# apollo4p register map
Vendor: Ambiq Micro; Series: Apollo; File version: 1.0
CPU: CM4 r1p0, little endian, MPU, FPU, I-cache, D-cache, VTOR, ITCM, DTCM, 3 interrupt priority bits, 0 interrupts
Registers are 32-bit, read-write, reset 0x0 unless marked. A register's access mark holds for its fields unless they carry their own. Offsets are from the block's base; [hi:lo] are bit positions; {n}, {i} and the like mark numbered series; 'fields as' and 'values as' point back to an identical list.

## GPIO (part 3 of 5) — General Purpose IO
Base 0x40010000
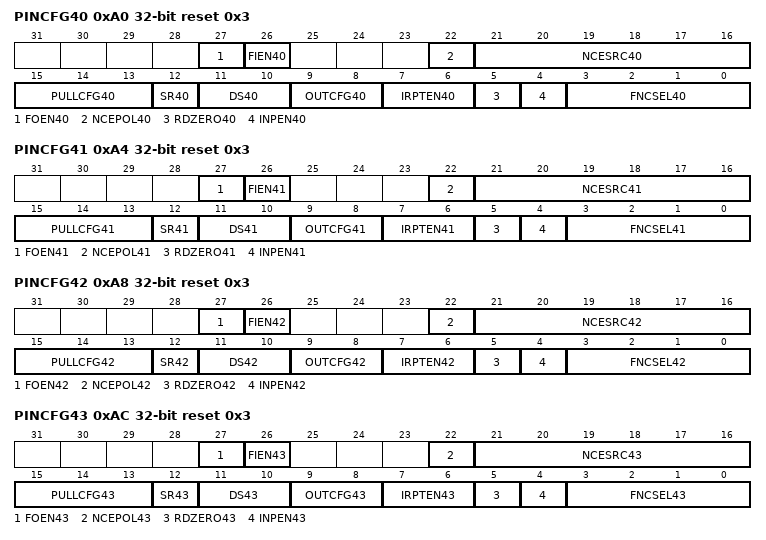
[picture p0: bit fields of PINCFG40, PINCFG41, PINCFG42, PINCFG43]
0xA0 PINCFG40 reset 0x3 — Controls the operation of GPIO pin 40.
  [27] FOEN40 — Force output enable active regardless of function selected. Otherwise the selected function will enable the output only when needed
  [26] FIEN40 — Force input enable active regardless of function selected. Otherwise the selected function will enable the input only when needed
  [22] NCEPOL40 — Polarity select for NCE for GPIO 40
    0=LOW (Polarity is active low); 1=HIGH (Polarity is active high)
  [21:16] NCESRC40 — IOMSTR/MSPI N Chip Select 40, DISP control signals DE, CSX, and CS. Polarity is determined by CE_POLARITY field
    {v}=IOM0CE{v} (IOM 0 NCE {v} module) (v=0..3); {v}=IOM1CE{v-4} (IOM 1 NCE {v-4} module) (v=4..7); {v}=IOM2CE{v-8} (IOM 2 NCE {v-8} module) (v=8..11); {v}=IOM3CE{v-12} (IOM 3 NCE {v-12} module) (v=12..15); {v}=IOM4CE{v-16} (IOM 4 NCE {v-16} module) (v=16..19); {v}=IOM5CE{v-20} (IOM 5 NCE {v-20} module) (v=20..23); {v}=IOM6CE{v-24} (IOM 6 NCE {v-24} module) (v=24..27); {v}=IOM7CE{v-28} (IOM 7 NCE {v-28} module) (v=28..31); 32=MSPI0CEN0 (MSPI 0 NCE 0 module); 33=MSPI0CEN1 (MSPI 0 NCE 1 module); 34=MSPI1CEN0 (MSPI 1 NCE 0 module); 35=MSPI1CEN1 (MSPI 1 NCE 1 module); 36=MSPI2CEN0 (MSPI 2 NCE 0 module); 37=MSPI2CEN1 (MSPI 2 NCE 1 module); 38=DC_DPI_DE (DC DPI DE module); 39=DISP_CONT_CSX (DISP CONT CSX module); 40=DC_SPI_CS_N (DC SPI CS_N module); 41=DC_QSPI_CS_N (DC QSPI CS_N module); 42=DC_RESX (DC module RESX)
  [15:13] PULLCFG40 — Pullup/Pulldown configuration for GPIO 40
    0=DIS (No pullup or pulldown selected); 1=PD50K (50K Pulldown selected); 2=PU15K (1.5K Pullup selected); 3=PU6K (6K Pullup selected); 4=PU12K (12K Pullup selected); 5=PU24K (24K Pullup selected); 6=PU50K (50K Pullup selected); 7=PU100K (100K Pullup selected)
  [12] SR40 — Configure the slew rate
  [11:10] DS40 — Drive strength selection for GPIO 40
    0=0P1X (0.1x output driver selected); 1=0P5X (0.5x output driver selected); 2=0P75X (0.75x output driver selected); 3=1P0X (1.0x output driver selected)
  [9:8] OUTCFG40 — Pin IO mode selection for GPIO pin 40
    0=DIS (Output Disabled); 1=PUSHPULL (Output configured in push pull mode. Will drive 0 and 1 values on pin.); 2=OD (Output configured in open drain mode. Will only drive pin low, tristate otherwise.); 3=TS (Output configured in Tristate-able push pull mode. Will drive 0, 1 of HiZ on pin.)
  [7:6] IRPTEN40 — Interrupt enable for GPIO 40
    0=DIS (Interrupts are disabled for this GPIO); 1=INTFALL (Interrupts are enabled for falling edge transition on this GPIO); 2=INTRISE (Interrupts are enabled for rising edge transitions on this GPIO); 3=INTANY (Interrupts are enabled for any edge transition on this GPIO)
  [5] RDZERO40 — Return 0 for read data on GPIO 40
  [4] INPEN40 — Input enable for GPIO 40
  [3:0] FNCSEL40 — Function select for GPIO pin 40
    0=MSPI1_3 (MSPI Master 1 Interface Signal); 1=TRIG1 (ADC trigger input); 2=SWTRACE1 (Serial Wire Debug Trace Output 1); 3=GPIO (General purpose I/O); 4=UART0CTS (UART Clear to Send (CTS) (UART 0)); 5=DISP_D18 (Display Data 18); 6=CT40 (Timer/Counter input or output; Selection of direction is done via CTIMER register settings.); 7=NCE40 (IOMSTR/MSPI N Chip Select. Polarity is determined by CE_POLARITY field); 8=OBSBUS8 (Observation bus bit 8); 11=FPIO (Fast PIO)
0xA4 PINCFG41 reset 0x3 — Controls the operation of GPIO pin 41.
  [27] FOEN41 — Force output enable active regardless of function selected. Otherwise the selected function will enable the output only when needed
  [26] FIEN41 — Force input enable active regardless of function selected. Otherwise the selected function will enable the input only when needed
  [22] NCEPOL41 — Polarity select for NCE for GPIO 41
    values as PINCFG40.NCEPOL40
  [21:16] NCESRC41 — IOMSTR/MSPI N Chip Select 41, DISP control signals DE, CSX, and CS. Polarity is determined by CE_POLARITY field
    values as PINCFG40.NCESRC40
  [15:13] PULLCFG41 — Pullup/Pulldown configuration for GPIO 41
    values as PINCFG40.PULLCFG40
  [12] SR41 — Configure the slew rate
  [11:10] DS41 — Drive strength selection for GPIO 41
    values as PINCFG40.DS40
  [9:8] OUTCFG41 — Pin IO mode selection for GPIO pin 41
    values as PINCFG40.OUTCFG40
  [7:6] IRPTEN41 — Interrupt enable for GPIO 41
    values as PINCFG40.IRPTEN40
  [5] RDZERO41 — Return 0 for read data on GPIO 41
  [4] INPEN41 — Input enable for GPIO 41
  [3:0] FNCSEL41 — Function select for GPIO pin 41
    0=MSPI1_4 (MSPI Master 1 Interface Signal); 1=TRIG0 (ADC trigger input); 2=SWTRACE2 (Serial Wire Debug Trace Output 2); 3=GPIO (General purpose I/O); 4=UART0TX (UART transmit output (UART 0)); 5=DISP_D19 (Display Data 19); 6=CT41 (Timer/Counter input or output; Selection of direction is done via CTIMER register settings.); 7=NCE41 (IOMSTR/MSPI N Chip Select. Polarity is determined by CE_POLARITY field); 8=OBSBUS9 (Observation bus bit 9); 9=SWO (Serial Wire Output); 11=FPIO (Fast PIO)
0xA8 PINCFG42 reset 0x3 — Controls the operation of GPIO pin 42.
  [27] FOEN42 — Force output enable active regardless of function selected. Otherwise the selected function will enable the output only when needed
  [26] FIEN42 — Force input enable active regardless of function selected. Otherwise the selected function will enable the input only when needed
  [22] NCEPOL42 — Polarity select for NCE for GPIO 42
    values as PINCFG40.NCEPOL40
  [21:16] NCESRC42 — IOMSTR/MSPI N Chip Select 42, DISP control signals DE, CSX, and CS. Polarity is determined by CE_POLARITY field
    values as PINCFG40.NCESRC40
  [15:13] PULLCFG42 — Pullup/Pulldown configuration for GPIO 42
    values as PINCFG40.PULLCFG40
  [12] SR42 — Configure the slew rate
  [11:10] DS42 — Drive strength selection for GPIO 42
    values as PINCFG40.DS40
  [9:8] OUTCFG42 — Pin IO mode selection for GPIO pin 42
    values as PINCFG40.OUTCFG40
  [7:6] IRPTEN42 — Interrupt enable for GPIO 42
    values as PINCFG40.IRPTEN40
  [5] RDZERO42 — Return 0 for read data on GPIO 42
  [4] INPEN42 — Input enable for GPIO 42
  [3:0] FNCSEL42 — Function select for GPIO pin 42
    0=MSPI1_5 (MSPI Master 1 Interface Signal); 1=TRIG2 (ADC trigger input); 2=SWTRACE3 (Serial Wire Debug Trace Output 3); 3=GPIO (General purpose I/O); 4=UART2TX (UART transmit output (UART 2)); 5=DISP_D20 (Display Data 20); 6=CT42 (Timer/Counter input or output; Selection of direction is done via CTIMER register settings.); 7=NCE42 (IOMSTR/MSPI N Chip Select. Polarity is determined by CE_POLARITY field); 8=OBSBUS10 (Observation bus bit 10); 11=FPIO (Fast PIO)
0xAC PINCFG43 reset 0x3 — Controls the operation of GPIO pin 43.
  [27] FOEN43 — Force output enable active regardless of function selected. Otherwise the selected function will enable the output only when needed
  [26] FIEN43 — Force input enable active regardless of function selected. Otherwise the selected function will enable the input only when needed
  [22] NCEPOL43 — Polarity select for NCE for GPIO 43
    values as PINCFG40.NCEPOL40
  [21:16] NCESRC43 — IOMSTR/MSPI N Chip Select 43, DISP control signals DE, CSX, and CS. Polarity is determined by CE_POLARITY field
    values as PINCFG40.NCESRC40
  [15:13] PULLCFG43 — Pullup/Pulldown configuration for GPIO 43
    values as PINCFG40.PULLCFG40
  [12] SR43 — Configure the slew rate
  [11:10] DS43 — Drive strength selection for GPIO 43
    values as PINCFG40.DS40
  [9:8] OUTCFG43 — Pin IO mode selection for GPIO pin 43
    values as PINCFG40.OUTCFG40
  [7:6] IRPTEN43 — Interrupt enable for GPIO 43
    values as PINCFG40.IRPTEN40
  [5] RDZERO43 — Return 0 for read data on GPIO 43
  [4] INPEN43 — Input enable for GPIO 43
  [3:0] FNCSEL43 — Function select for GPIO pin 43
    0=MSPI1_6 (MSPI Master 1 Interface Signal); 1=TRIG3 (ADC trigger input); 2=SWTRACECTL (Serial Wire Debug Trace Control); 3=GPIO (General purpose I/O); 4=UART0RX (UART receive input (UART 0)); 5=DISP_D21 (Display Data 21); 6=CT43 (Timer/Counter input or output; Selection of direction is done via CTIMER register settings.); 7=NCE43 (IOMSTR/MSPI N Chip Select. Polarity is determined by CE_POLARITY field); 8=OBSBUS11 (Observation bus bit 11); 11=FPIO (Fast PIO)
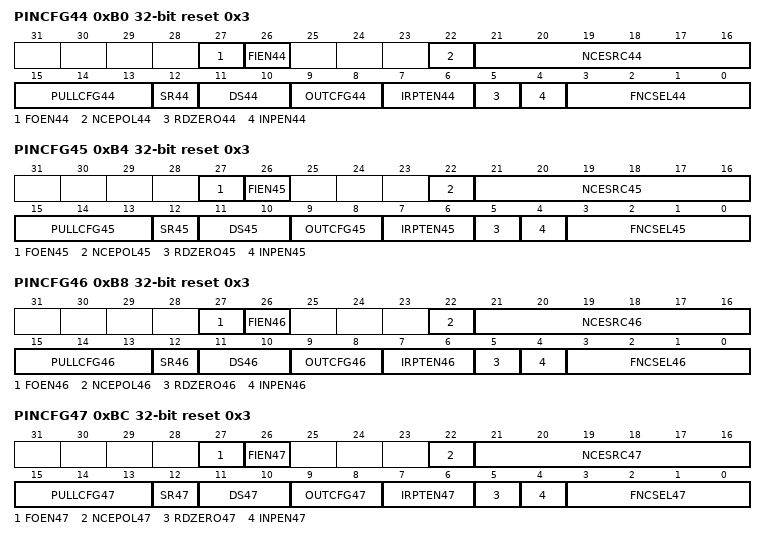
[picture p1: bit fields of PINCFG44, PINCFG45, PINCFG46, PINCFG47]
0xB0 PINCFG44 reset 0x3 — Controls the operation of GPIO pin 44.
  [27] FOEN44 — Force output enable active regardless of function selected. Otherwise the selected function will enable the output only when needed
  [26] FIEN44 — Force input enable active regardless of function selected. Otherwise the selected function will enable the input only when needed
  [22] NCEPOL44 — Polarity select for NCE for GPIO 44
    values as PINCFG40.NCEPOL40
  [21:16] NCESRC44 — IOMSTR/MSPI N Chip Select 44, DISP control signals DE, CSX, and CS. Polarity is determined by CE_POLARITY field
    values as PINCFG40.NCESRC40
  [15:13] PULLCFG44 — Pullup/Pulldown configuration for GPIO 44
    values as PINCFG40.PULLCFG40
  [12] SR44 — Configure the slew rate
  [11:10] DS44 — Drive strength selection for GPIO 44
    values as PINCFG40.DS40
  [9:8] OUTCFG44 — Pin IO mode selection for GPIO pin 44
    values as PINCFG40.OUTCFG40
  [7:6] IRPTEN44 — Interrupt enable for GPIO 44
    values as PINCFG40.IRPTEN40
  [5] RDZERO44 — Return 0 for read data on GPIO 44
  [4] INPEN44 — Input enable for GPIO 44
  [3:0] FNCSEL44 — Function select for GPIO pin 44
    0=MSPI1_7 (MSPI Master 1 Interface Signal); 1=TRIG1 (ADC trigger input); 2=SWO (Serial Wire Output); 3=GPIO (General purpose I/O); 4=UART2RX (UART receive input (UART 2)); 5=DISP_D22 (Display Data 22); 6=CT44 (Timer/Counter input or output; Selection of direction is done via CTIMER register settings.); 7=NCE44 (IOMSTR/MSPI N Chip Select. Polarity is determined by CE_POLARITY field); 8=OBSBUS12 (Observation bus bit 12); 9=VCMPO (Output of the voltage comparator signal); 11=FPIO (Fast PIO)
0xB4 PINCFG45 reset 0x3 — Controls the operation of GPIO pin 45.
  [27] FOEN45 — Force output enable active regardless of function selected. Otherwise the selected function will enable the output only when needed
  [26] FIEN45 — Force input enable active regardless of function selected. Otherwise the selected function will enable the input only when needed
  [22] NCEPOL45 — Polarity select for NCE for GPIO 45
    values as PINCFG40.NCEPOL40
  [21:16] NCESRC45 — IOMSTR/MSPI N Chip Select 45, DISP control signals DE, CSX, and CS. Polarity is determined by CE_POLARITY field
    values as PINCFG40.NCESRC40
  [15:13] PULLCFG45 — Pullup/Pulldown configuration for GPIO 45
    values as PINCFG40.PULLCFG40
  [12] SR45 — Configure the slew rate
  [11:10] DS45 — Drive strength selection for GPIO 45
    values as PINCFG40.DS40
  [9:8] OUTCFG45 — Pin IO mode selection for GPIO pin 45
    values as PINCFG40.OUTCFG40
  [7:6] IRPTEN45 — Interrupt enable for GPIO 45
    values as PINCFG40.IRPTEN40
  [5] RDZERO45 — Return 0 for read data on GPIO 45
  [4] INPEN45 — Input enable for GPIO 45
  [3:0] FNCSEL45 — Function select for GPIO pin 45
    0=MSPI1_8 (MSPI Master 1 Interface Signal); 1=TRIG2 (ADC trigger input); 2=32KHzXT (32kHZ from analog); 3=GPIO (General purpose I/O); 4=UART0TX (UART transmit output (UART 0)); 5=DISP_D23 (Display Data 23); 6=CT45 (Timer/Counter input or output; Selection of direction is done via CTIMER register settings.); 7=NCE45 (IOMSTR/MSPI N Chip Select. Polarity is determined by CE_POLARITY field); 8=OBSBUS13 (Observation bus bit 13); 11=FPIO (Fast PIO)
0xB8 PINCFG46 reset 0x3 — Controls the operation of GPIO pin 46.
  [27] FOEN46 — Force output enable active regardless of function selected. Otherwise the selected function will enable the output only when needed
  [26] FIEN46 — Force input enable active regardless of function selected. Otherwise the selected function will enable the input only when needed
  [22] NCEPOL46 — Polarity select for NCE for GPIO 46
    values as PINCFG40.NCEPOL40
  [21:16] NCESRC46 — IOMSTR/MSPI N Chip Select 46, DISP control signals DE, CSX, and CS. Polarity is determined by CE_POLARITY field
    values as PINCFG40.NCESRC40
  [15:13] PULLCFG46 — Pullup/Pulldown configuration for GPIO 46
    values as PINCFG40.PULLCFG40
  [12] SR46 — Configure the slew rate
  [11:10] DS46 — Drive strength selection for GPIO 46
    values as PINCFG40.DS40
  [9:8] OUTCFG46 — Pin IO mode selection for GPIO pin 46
    values as PINCFG40.OUTCFG40
  [7:6] IRPTEN46 — Interrupt enable for GPIO 46
    values as PINCFG40.IRPTEN40
  [5] RDZERO46 — Return 0 for read data on GPIO 46
  [4] INPEN46 — Input enable for GPIO 46
  [3:0] FNCSEL46 — Function select for GPIO pin 46
    0=MSPI1_9 (MSPI Master 1 Interface Signal); 1=TRIG3 (ADC trigger input); 2=CLKOUT_32M (32MHz Oscillator output clock); 3=GPIO (General purpose I/O); 4=UART2TX (UART transmit output (UART 2)); 5=UART3TX (UART transmit output (UART 3)); 6=CT46 (Timer/Counter input or output; Selection of direction is done via CTIMER register settings.); 7=NCE46 (IOMSTR/MSPI N Chip Select. Polarity is determined by CE_POLARITY field); 8=OBSBUS14 (Observation bus bit 14); 9=I2S1_SDIN (I2S Data input (I2S Master/Slave 2)); 10=I2S0_SDIN (I2S Data input (I2S Master/Slave 2)); 11=FPIO (Fast PIO)
0xBC PINCFG47 reset 0x3 — Controls the operation of GPIO pin 47.
  [27] FOEN47 — Force output enable active regardless of function selected. Otherwise the selected function will enable the output only when needed
  [26] FIEN47 — Force input enable active regardless of function selected. Otherwise the selected function will enable the input only when needed
  [22] NCEPOL47 — Polarity select for NCE for GPIO 47
    values as PINCFG40.NCEPOL40
  [21:16] NCESRC47 — IOMSTR/MSPI N Chip Select 47, DISP control signals DE, CSX, and CS. Polarity is determined by CE_POLARITY field
    values as PINCFG40.NCESRC40
  [15:13] PULLCFG47 — Pullup/Pulldown configuration for GPIO 47
    values as PINCFG40.PULLCFG40
  [12] SR47 — Configure the slew rate
  [11:10] DS47 — Drive strength selection for GPIO 47
    values as PINCFG40.DS40
  [9:8] OUTCFG47 — Pin IO mode selection for GPIO pin 47
    values as PINCFG40.OUTCFG40
  [7:6] IRPTEN47 — Interrupt enable for GPIO 47
    values as PINCFG40.IRPTEN40
  [5] RDZERO47 — Return 0 for read data on GPIO 47
  [4] INPEN47 — Input enable for GPIO 47
  [3:0] FNCSEL47 — Function select for GPIO pin 47
    0=M5SCL (Serial I2C Master Clock output (IOM 5)); 1=M5SCK (Serial SPI Master Clock output (IOM 5)); 2=I2S1_CLK (Bidirectional I2S Bit clock. Operates in output mode in master mode and input mode for slave mode. (I2S Master/Slave 2)); 3=GPIO (General purpose I/O); 4=UART0RX (UART receive input (UART 0)); 5=UART1RX (UART receive input (UART 1)); 6=CT47 (Timer/Counter input or output; Selection of direction is done via CTIMER register settings.); 7=NCE47 (IOMSTR/MSPI N Chip Select. Polarity is determined by CE_POLARITY field); 8=OBSBUS15 (Observation bus bit 15); 10=I2S0_CLK (Bidirectional I2S Bit clock. Operates in output mode in master mode and input mode for slave mode. (I2S Master/Slave 2)); 11=FPIO (Fast PIO)
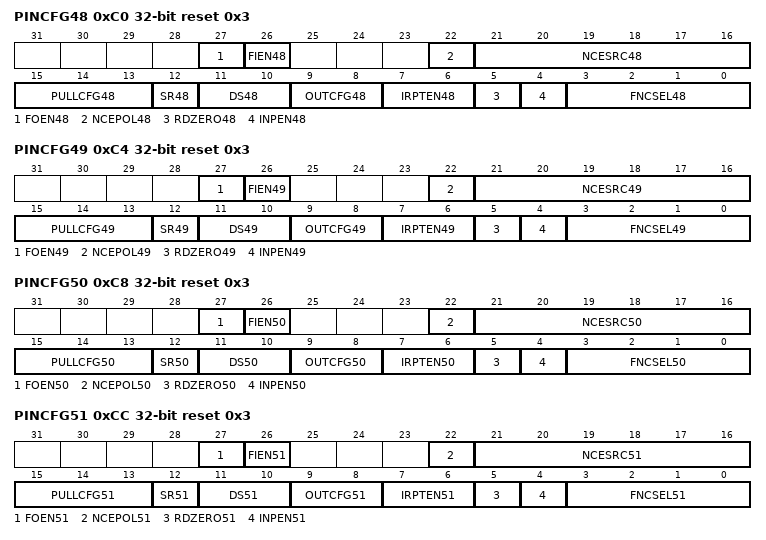
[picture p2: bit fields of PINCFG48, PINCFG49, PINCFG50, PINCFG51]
0xC0 PINCFG48 reset 0x3 — Controls the operation of GPIO pin 48.
  [27] FOEN48 — Force output enable active regardless of function selected. Otherwise the selected function will enable the output only when needed
  [26] FIEN48 — Force input enable active regardless of function selected. Otherwise the selected function will enable the input only when needed
  [22] NCEPOL48 — Polarity select for NCE for GPIO 48
    values as PINCFG40.NCEPOL40
  [21:16] NCESRC48 — IOMSTR/MSPI N Chip Select 48, DISP control signals DE, CSX, and CS. Polarity is determined by CE_POLARITY field
    values as PINCFG40.NCESRC40
  [15:13] PULLCFG48 — Pullup/Pulldown configuration for GPIO 48
    values as PINCFG40.PULLCFG40
  [12] SR48 — Configure the slew rate
  [11:10] DS48 — Drive strength selection for GPIO 48
    values as PINCFG40.DS40
  [9:8] OUTCFG48 — Pin IO mode selection for GPIO pin 48
    values as PINCFG40.OUTCFG40
  [7:6] IRPTEN48 — Interrupt enable for GPIO 48
    values as PINCFG40.IRPTEN40
  [5] RDZERO48 — Return 0 for read data on GPIO 48
  [4] INPEN48 — Input enable for GPIO 48
  [3:0] FNCSEL48 — Function select for GPIO pin 48
    0=M5SDAWIR3 (Serial I2C Master Data I/O (I2C Mode) Serial SPI Master Data I/O (SPI 3 wire mode) (IOM 5)); 1=M5MOSI (Serial SPI Master MOSI output (IOM 5)); 2=I2S1_DATA (Bidirectional I2S Data. Operates in output mode in master mode and input mode for slave mode. (I2S Master/Slave 2)); 3=GPIO (General purpose I/O); 4=UART2RX (UART receive input (UART 2)); 5=UART3RX (UART receive input (UART 3)); 6=CT48 (Timer/Counter input or output; Selection of direction is done via CTIMER register settings.); 7=NCE48 (IOMSTR/MSPI N Chip Select. Polarity is determined by CE_POLARITY field); 8=OBSBUS0 (Observation bus bit 0); 9=I2S1_SDOUT (I2S Data output (I2S Master/Slave 2)); 10=I2S0_SDOUT (I2S Data output (I2S Master/Slave 2)); 11=FPIO (Fast PIO)
0xC4 PINCFG49 reset 0x3 — Controls the operation of GPIO pin 49.
  [27] FOEN49 — Force output enable active regardless of function selected. Otherwise the selected function will enable the output only when needed
  [26] FIEN49 — Force input enable active regardless of function selected. Otherwise the selected function will enable the input only when needed
  [22] NCEPOL49 — Polarity select for NCE for GPIO 49
    values as PINCFG40.NCEPOL40
  [21:16] NCESRC49 — IOMSTR/MSPI N Chip Select 49, DISP control signals DE, CSX, and CS. Polarity is determined by CE_POLARITY field
    values as PINCFG40.NCESRC40
  [15:13] PULLCFG49 — Pullup/Pulldown configuration for GPIO 49
    values as PINCFG40.PULLCFG40
  [12] SR49 — Configure the slew rate
  [11:10] DS49 — Drive strength selection for GPIO 49
    values as PINCFG40.DS40
  [9:8] OUTCFG49 — Pin IO mode selection for GPIO pin 49
    values as PINCFG40.OUTCFG40
  [7:6] IRPTEN49 — Interrupt enable for GPIO 49
    values as PINCFG40.IRPTEN40
  [5] RDZERO49 — Return 0 for read data on GPIO 49
  [4] INPEN49 — Input enable for GPIO 49
  [3:0] FNCSEL49 — Function select for GPIO pin 49
    0=M5MISO (Serial SPI MASTER MISO input (IOM 5)); 1=TRIG0 (ADC trigger input); 2=I2S1_WS (Bidirectional I2S L/R clock. Operates in output mode in master mode and input mode for slave mode. (I2S Master/Slave 2)); 3=GPIO (General purpose I/O); 4=UART0RTS (UART Request to Send (RTS) (UART 0)); 5=UART1RTS (UART Request to Send (RTS) (UART 1)); 6=CT49 (Timer/Counter input or output; Selection of direction is done via CTIMER register settings.); 7=NCE49 (IOMSTR/MSPI N Chip Select. Polarity is determined by CE_POLARITY field); 8=OBSBUS1 (Observation bus bit 1); 10=I2S0_WS (Bidirectional I2S L/R clock. Operates in output mode in master mode and input mode for slave mode. (I2S Master/Slave 2)); 11=FPIO (Fast PIO)
0xC8 PINCFG50 reset 0x3 — Controls the operation of GPIO pin 50.
  [27] FOEN50 — Force output enable active regardless of function selected. Otherwise the selected function will enable the output only when needed
  [26] FIEN50 — Force input enable active regardless of function selected. Otherwise the selected function will enable the input only when needed
  [22] NCEPOL50 — Polarity select for NCE for GPIO 50
    values as PINCFG40.NCEPOL40
  [21:16] NCESRC50 — IOMSTR/MSPI N Chip Select 50, DISP control signals DE, CSX, and CS. Polarity is determined by CE_POLARITY field
    values as PINCFG40.NCESRC40
  [15:13] PULLCFG50 — Pullup/Pulldown configuration for GPIO 50
    values as PINCFG40.PULLCFG40
  [12] SR50 — Configure the slew rate
  [11:10] DS50 — Drive strength selection for GPIO 50
    0=0P1X (0.1x output driver selected); 1=0P5X (0.5x output driver selected)
  [9:8] OUTCFG50 — Pin IO mode selection for GPIO pin 50
    values as PINCFG40.OUTCFG40
  [7:6] IRPTEN50 — Interrupt enable for GPIO 50
    values as PINCFG40.IRPTEN40
  [5] RDZERO50 — Return 0 for read data on GPIO 50
  [4] INPEN50 — Input enable for GPIO 50
  [3:0] FNCSEL50 — Function select for GPIO pin 50
    0=PDM0_CLK (PDMx Clock output (I2C Master/Slave D)); 1=TRIG0 (ADC trigger input); 2=SWTRACECLK (Serial Wire Debug Trace Clock); 3=GPIO (General purpose I/O); 4=UART2RTS (UART Request to Send (RTS) (UART 2)); 5=UART3RTS (UART Request to Send (RTS) (UART 3)); 6=CT50 (Timer/Counter input or output; Selection of direction is done via CTIMER register settings.); 7=NCE50 (IOMSTR/MSPI N Chip Select. Polarity is determined by CE_POLARITY field); 8=OBSBUS2 (Observation bus bit 2); 9=DISP_TE (Display TE input); 11=FPIO (Fast PIO)
0xCC PINCFG51 reset 0x3 — Controls the operation of GPIO pin 51.
  [27] FOEN51 — Force output enable active regardless of function selected. Otherwise the selected function will enable the output only when needed
  [26] FIEN51 — Force input enable active regardless of function selected. Otherwise the selected function will enable the input only when needed
  [22] NCEPOL51 — Polarity select for NCE for GPIO 51
    values as PINCFG40.NCEPOL40
  [21:16] NCESRC51 — IOMSTR/MSPI N Chip Select 51, DISP control signals DE, CSX, and CS. Polarity is determined by CE_POLARITY field
    values as PINCFG40.NCESRC40
  [15:13] PULLCFG51 — Pullup/Pulldown configuration for GPIO 51
    values as PINCFG40.PULLCFG40
  [12] SR51 — Configure the slew rate
  [11:10] DS51 — Drive strength selection for GPIO 51
    values as PINCFG40.DS40
  [9:8] OUTCFG51 — Pin IO mode selection for GPIO pin 51
    values as PINCFG40.OUTCFG40
  [7:6] IRPTEN51 — Interrupt enable for GPIO 51
    values as PINCFG40.IRPTEN40
  [5] RDZERO51 — Return 0 for read data on GPIO 51
  [4] INPEN51 — Input enable for GPIO 51
  [3:0] FNCSEL51 — Function select for GPIO pin 51
    0=PDM0_DATA (PDMx audio data input to chip (I2C Master/Slave D)); 1=TRIG1 (ADC trigger input); 2=SWTRACE0 (Serial Wire Debug Trace Output 0); 3=GPIO (General purpose I/O); 4=UART0CTS (UART Clear to Send (CTS) (UART 0)); 5=UART1CTS (UART Clear to Send (CTS) (UART 1)); 6=CT51 (Timer/Counter input or output; Selection of direction is done via CTIMER register settings.); 7=NCE51 (IOMSTR/MSPI N Chip Select. Polarity is determined by CE_POLARITY field); 8=OBSBUS3 (Observation bus bit 3); 11=FPIO (Fast PIO)
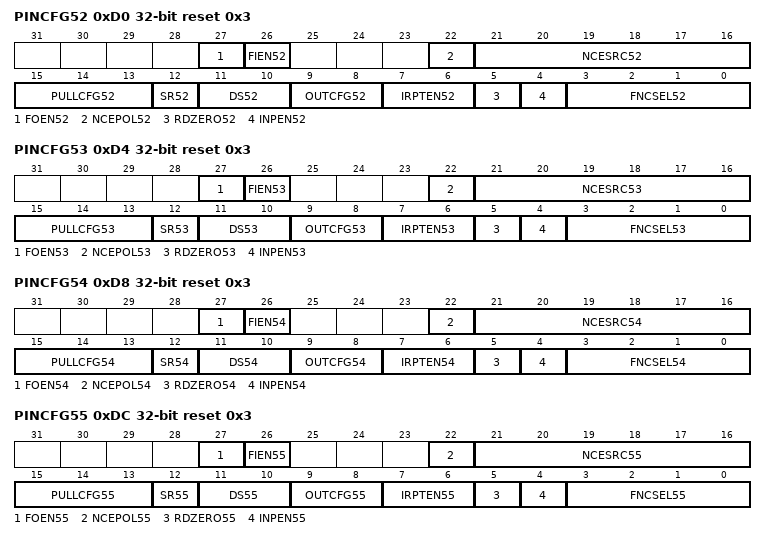
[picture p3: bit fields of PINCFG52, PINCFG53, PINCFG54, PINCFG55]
0xD0 PINCFG52 reset 0x3 — Controls the operation of GPIO pin 52.
  [27] FOEN52 — Force output enable active regardless of function selected. Otherwise the selected function will enable the output only when needed
  [26] FIEN52 — Force input enable active regardless of function selected. Otherwise the selected function will enable the input only when needed
  [22] NCEPOL52 — Polarity select for NCE for GPIO 52
    values as PINCFG40.NCEPOL40
  [21:16] NCESRC52 — IOMSTR/MSPI N Chip Select 52, DISP control signals DE, CSX, and CS. Polarity is determined by CE_POLARITY field
    values as PINCFG40.NCESRC40
  [15:13] PULLCFG52 — Pullup/Pulldown configuration for GPIO 52
    values as PINCFG40.PULLCFG40
  [12] SR52 — Configure the slew rate
  [11:10] DS52 — Drive strength selection for GPIO 52
    values as PINCFG40.DS40
  [9:8] OUTCFG52 — Pin IO mode selection for GPIO pin 52
    values as PINCFG40.OUTCFG40
  [7:6] IRPTEN52 — Interrupt enable for GPIO 52
    values as PINCFG40.IRPTEN40
  [5] RDZERO52 — Return 0 for read data on GPIO 52
  [4] INPEN52 — Input enable for GPIO 52
  [3:0] FNCSEL52 — Function select for GPIO pin 52
    0=PDM1_CLK (PDMx Clock output (I2C Master/Slave D)); 1=TRIG2 (ADC trigger input); 2=SWTRACE1 (Serial Wire Debug Trace Output 1); 3=GPIO (General purpose I/O); 4=UART2CTS (UART Clear to Send (CTS) (UART 2)); 5=UART3CTS (UART Clear to Send (CTS) (UART 3)); 6=CT52 (Timer/Counter input or output; Selection of direction is done via CTIMER register settings.); 7=NCE52 (IOMSTR/MSPI N Chip Select. Polarity is determined by CE_POLARITY field); 8=OBSBUS4 (Observation bus bit 4); 9=VCMPO (Output of the voltage comparator signal); 11=FPIO (Fast PIO)
0xD4 PINCFG53 reset 0x3 — Controls the operation of GPIO pin 53.
  [27] FOEN53 — Force output enable active regardless of function selected. Otherwise the selected function will enable the output only when needed
  [26] FIEN53 — Force input enable active regardless of function selected. Otherwise the selected function will enable the input only when needed
  [22] NCEPOL53 — Polarity select for NCE for GPIO 53
    values as PINCFG40.NCEPOL40
  [21:16] NCESRC53 — IOMSTR/MSPI N Chip Select 53, DISP control signals DE, CSX, and CS. Polarity is determined by CE_POLARITY field
    values as PINCFG40.NCESRC40
  [15:13] PULLCFG53 — Pullup/Pulldown configuration for GPIO 53
    values as PINCFG40.PULLCFG40
  [12] SR53 — Configure the slew rate
  [11:10] DS53 — Drive strength selection for GPIO 53
    values as PINCFG40.DS40
  [9:8] OUTCFG53 — Pin IO mode selection for GPIO pin 53
    values as PINCFG40.OUTCFG40
  [7:6] IRPTEN53 — Interrupt enable for GPIO 53
    values as PINCFG40.IRPTEN40
  [5] RDZERO53 — Return 0 for read data on GPIO 53
  [4] INPEN53 — Input enable for GPIO 53
  [3:0] FNCSEL53 — Function select for GPIO pin 53
    0=PDM1_DATA (PDMx audio data input to chip (I2C Master/Slave D)); 1=TRIG3 (ADC trigger input); 2=SWTRACE2 (Serial Wire Debug Trace Output 2); 3=GPIO (General purpose I/O); 4=UART0TX (UART transmit output (UART 0)); 5=UART1TX (UART transmit output (UART 1)); 6=CT53 (Timer/Counter input or output; Selection of direction is done via CTIMER register settings.); 7=NCE53 (IOMSTR/MSPI N Chip Select. Polarity is determined by CE_POLARITY field); 8=OBSBUS5 (Observation bus bit 5); 11=FPIO (Fast PIO)
0xD8 PINCFG54 reset 0x3 — Controls the operation of GPIO pin 54.
  [27] FOEN54 — Force output enable active regardless of function selected. Otherwise the selected function will enable the output only when needed
  [26] FIEN54 — Force input enable active regardless of function selected. Otherwise the selected function will enable the input only when needed
  [22] NCEPOL54 — Polarity select for NCE for GPIO 54
    values as PINCFG40.NCEPOL40
  [21:16] NCESRC54 — IOMSTR/MSPI N Chip Select 54, DISP control signals DE, CSX, and CS. Polarity is determined by CE_POLARITY field
    values as PINCFG40.NCESRC40
  [15:13] PULLCFG54 — Pullup/Pulldown configuration for GPIO 54
    values as PINCFG40.PULLCFG40
  [12] SR54 — Configure the slew rate
  [11:10] DS54 — Drive strength selection for GPIO 54
    values as PINCFG40.DS40
  [9:8] OUTCFG54 — Pin IO mode selection for GPIO pin 54
    values as PINCFG40.OUTCFG40
  [7:6] IRPTEN54 — Interrupt enable for GPIO 54
    values as PINCFG40.IRPTEN40
  [5] RDZERO54 — Return 0 for read data on GPIO 54
  [4] INPEN54 — Input enable for GPIO 54
  [3:0] FNCSEL54 — Function select for GPIO pin 54
    0=PDM2_CLK (PDMx Clock output (I2C Master/Slave D)); 1=TRIG0 (ADC trigger input); 2=SWTRACE3 (Serial Wire Debug Trace Output 3); 3=GPIO (General purpose I/O); 4=UART2TX (UART transmit output (UART 2)); 5=UART3TX (UART transmit output (UART 3)); 6=CT54 (Timer/Counter input or output; Selection of direction is done via CTIMER register settings.); 7=NCE54 (IOMSTR/MSPI N Chip Select. Polarity is determined by CE_POLARITY field); 8=OBSBUS6 (Observation bus bit 6); 11=FPIO (Fast PIO)
0xDC PINCFG55 reset 0x3 — Controls the operation of GPIO pin 55.
  [27] FOEN55 — Force output enable active regardless of function selected. Otherwise the selected function will enable the output only when needed
  [26] FIEN55 — Force input enable active regardless of function selected. Otherwise the selected function will enable the input only when needed
  [22] NCEPOL55 — Polarity select for NCE for GPIO 55
    values as PINCFG40.NCEPOL40
  [21:16] NCESRC55 — IOMSTR/MSPI N Chip Select 55, DISP control signals DE, CSX, and CS. Polarity is determined by CE_POLARITY field
    values as PINCFG40.NCESRC40
  [15:13] PULLCFG55 — Pullup/Pulldown configuration for GPIO 55
    values as PINCFG40.PULLCFG40
  [12] SR55 — Configure the slew rate
  [11:10] DS55 — Drive strength selection for GPIO 55
    values as PINCFG40.DS40
  [9:8] OUTCFG55 — Pin IO mode selection for GPIO pin 55
    values as PINCFG40.OUTCFG40
  [7:6] IRPTEN55 — Interrupt enable for GPIO 55
    values as PINCFG40.IRPTEN40
  [5] RDZERO55 — Return 0 for read data on GPIO 55
  [4] INPEN55 — Input enable for GPIO 55
  [3:0] FNCSEL55 — Function select for GPIO pin 55
    0=PDM2_DATA (PDMx audio data input to chip (I2C Master/Slave D)); 1=TRIG1 (ADC trigger input); 2=SWTRACECTL (Serial Wire Debug Trace Control); 3=GPIO (General purpose I/O); 4=UART0RX (UART receive input (UART 0)); 5=UART1RX (UART receive input (UART 1)); 6=CT55 (Timer/Counter input or output; Selection of direction is done via CTIMER register settings.); 7=NCE55 (IOMSTR/MSPI N Chip Select. Polarity is determined by CE_POLARITY field); 8=OBSBUS7 (Observation bus bit 7); 11=FPIO (Fast PIO)
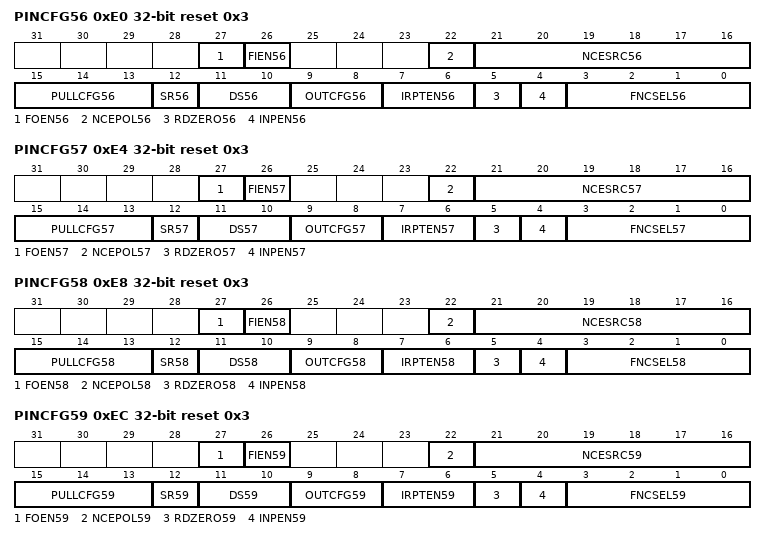
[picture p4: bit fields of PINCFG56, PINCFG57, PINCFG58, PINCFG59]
0xE0 PINCFG56 reset 0x3 — Controls the operation of GPIO pin 56.
  [27] FOEN56 — Force output enable active regardless of function selected. Otherwise the selected function will enable the output only when needed
  [26] FIEN56 — Force input enable active regardless of function selected. Otherwise the selected function will enable the input only when needed
  [22] NCEPOL56 — Polarity select for NCE for GPIO 56
    values as PINCFG40.NCEPOL40
  [21:16] NCESRC56 — IOMSTR/MSPI N Chip Select 56, DISP control signals DE, CSX, and CS. Polarity is determined by CE_POLARITY field
    values as PINCFG40.NCESRC40
  [15:13] PULLCFG56 — Pullup/Pulldown configuration for GPIO 56
    values as PINCFG40.PULLCFG40
  [12] SR56 — Configure the slew rate
  [11:10] DS56 — Drive strength selection for GPIO 56
    values as PINCFG40.DS40
  [9:8] OUTCFG56 — Pin IO mode selection for GPIO pin 56
    values as PINCFG40.OUTCFG40
  [7:6] IRPTEN56 — Interrupt enable for GPIO 56
    values as PINCFG40.IRPTEN40
  [5] RDZERO56 — Return 0 for read data on GPIO 56
  [4] INPEN56 — Input enable for GPIO 56
  [3:0] FNCSEL56 — Function select for GPIO pin 56
    0=PDM3_CLK (PDMx Clock output (I2C Master/Slave D)); 1=TRIG2 (ADC trigger input); 2=SWO (Serial Wire Output); 3=GPIO (General purpose I/O); 4=UART2RX (UART receive input (UART 2)); 5=UART3RX (UART receive input (UART 3)); 6=CT56 (Timer/Counter input or output; Selection of direction is done via CTIMER register settings.); 7=NCE56 (IOMSTR/MSPI N Chip Select. Polarity is determined by CE_POLARITY field); 8=OBSBUS8 (Observation bus bit 8); 11=FPIO (Fast PIO)
0xE4 PINCFG57 reset 0x3 — Controls the operation of GPIO pin 57.
  [27] FOEN57 — Force output enable active regardless of function selected. Otherwise the selected function will enable the output only when needed
  [26] FIEN57 — Force input enable active regardless of function selected. Otherwise the selected function will enable the input only when needed
  [22] NCEPOL57 — Polarity select for NCE for GPIO 57
    values as PINCFG40.NCEPOL40
  [21:16] NCESRC57 — IOMSTR/MSPI N Chip Select 57, DISP control signals DE, CSX, and CS. Polarity is determined by CE_POLARITY field
    values as PINCFG40.NCESRC40
  [15:13] PULLCFG57 — Pullup/Pulldown configuration for GPIO 57
    values as PINCFG40.PULLCFG40
  [12] SR57 — Configure the slew rate
  [11:10] DS57 — Drive strength selection for GPIO 57
    values as PINCFG40.DS40
  [9:8] OUTCFG57 — Pin IO mode selection for GPIO pin 57
    values as PINCFG40.OUTCFG40
  [7:6] IRPTEN57 — Interrupt enable for GPIO 57
    values as PINCFG40.IRPTEN40
  [5] RDZERO57 — Return 0 for read data on GPIO 57
  [4] INPEN57 — Input enable for GPIO 57
  [3:0] FNCSEL57 — Function select for GPIO pin 57
    0=PDM3_DATA (PDMx audio data input to chip (I2C Master/Slave D)); 1=TRIG3 (ADC trigger input); 2=SWO (Serial Wire Output); 3=GPIO (General purpose I/O); 4=UART0RTS (UART Request to Send (RTS) (UART 0)); 5=UART1RTS (UART Request to Send (RTS) (UART 1)); 6=CT57 (Timer/Counter input or output; Selection of direction is done via CTIMER register settings.); 7=NCE57 (IOMSTR/MSPI N Chip Select. Polarity is determined by CE_POLARITY field); 8=OBSBUS9 (Observation bus bit 9); 9=VCMPO (Output of the voltage comparator signal); 11=FPIO (Fast PIO)
0xE8 PINCFG58 reset 0x3 — Controls the operation of GPIO pin 58.
  [27] FOEN58 — Force output enable active regardless of function selected. Otherwise the selected function will enable the output only when needed
  [26] FIEN58 — Force input enable active regardless of function selected. Otherwise the selected function will enable the input only when needed
  [22] NCEPOL58 — Polarity select for NCE for GPIO 58
    values as PINCFG40.NCEPOL40
  [21:16] NCESRC58 — IOMSTR/MSPI N Chip Select 58, DISP control signals DE, CSX, and CS. Polarity is determined by CE_POLARITY field
    values as PINCFG40.NCESRC40
  [15:13] PULLCFG58 — Pullup/Pulldown configuration for GPIO 58
    values as PINCFG40.PULLCFG40
  [12] SR58 — Configure the slew rate
  [11:10] DS58 — Drive strength selection for GPIO 58
    values as PINCFG50.DS50
  [9:8] OUTCFG58 — Pin IO mode selection for GPIO pin 58
    values as PINCFG40.OUTCFG40
  [7:6] IRPTEN58 — Interrupt enable for GPIO 58
    values as PINCFG40.IRPTEN40
  [5] RDZERO58 — Return 0 for read data on GPIO 58
  [4] INPEN58 — Input enable for GPIO 58
  [3:0] FNCSEL58 — Function select for GPIO pin 58
    3=GPIO (General purpose I/O); 4=UART0RTS (UART Request to Send (RTS) (UART 0)); 5=UART3RTS (UART Request to Send (RTS) (UART 3)); 6=CT58 (Timer/Counter input or output; Selection of direction is done via CTIMER register settings.); 7=NCE58 (IOMSTR/MSPI N Chip Select. Polarity is determined by CE_POLARITY field); 8=OBSBUS10 (Observation bus bit 10); 11=FPIO (Fast PIO)
0xEC PINCFG59 reset 0x3 — Controls the operation of GPIO pin 59.
  [27] FOEN59 — Force output enable active regardless of function selected. Otherwise the selected function will enable the output only when needed
  [26] FIEN59 — Force input enable active regardless of function selected. Otherwise the selected function will enable the input only when needed
  [22] NCEPOL59 — Polarity select for NCE for GPIO 59
    values as PINCFG40.NCEPOL40
  [21:16] NCESRC59 — IOMSTR/MSPI N Chip Select 59, DISP control signals DE, CSX, and CS. Polarity is determined by CE_POLARITY field
    values as PINCFG40.NCESRC40
  [15:13] PULLCFG59 — Pullup/Pulldown configuration for GPIO 59
    values as PINCFG40.PULLCFG40
  [12] SR59 — Configure the slew rate
  [11:10] DS59 — Drive strength selection for GPIO 59
    values as PINCFG50.DS50
  [9:8] OUTCFG59 — Pin IO mode selection for GPIO pin 59
    values as PINCFG40.OUTCFG40
  [7:6] IRPTEN59 — Interrupt enable for GPIO 59
    values as PINCFG40.IRPTEN40
  [5] RDZERO59 — Return 0 for read data on GPIO 59
  [4] INPEN59 — Input enable for GPIO 59
  [3:0] FNCSEL59 — Function select for GPIO pin 59
    1=TRIG0 (ADC trigger input); 3=GPIO (General purpose I/O); 4=UART0CTS (UART Clear to Send (CTS) (UART 0)); 5=UART1CTS (UART Clear to Send (CTS) (UART 1)); 6=CT59 (Timer/Counter input or output; Selection of direction is done via CTIMER register settings.); 7=NCE59 (IOMSTR/MSPI N Chip Select. Polarity is determined by CE_POLARITY field); 8=OBSBUS11 (Observation bus bit 11); 11=FPIO (Fast PIO)
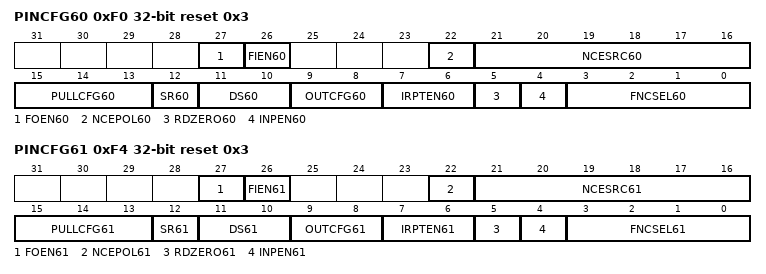
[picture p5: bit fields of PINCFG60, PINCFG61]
0xF0 PINCFG60 reset 0x3 — Controls the operation of GPIO pin 60.
  [27] FOEN60 — Force output enable active regardless of function selected. Otherwise the selected function will enable the output only when needed
  [26] FIEN60 — Force input enable active regardless of function selected. Otherwise the selected function will enable the input only when needed
  [22] NCEPOL60 — Polarity select for NCE for GPIO 60
    values as PINCFG40.NCEPOL40
  [21:16] NCESRC60 — IOMSTR/MSPI N Chip Select 60, DISP control signals DE, CSX, and CS. Polarity is determined by CE_POLARITY field
    values as PINCFG40.NCESRC40
  [15:13] PULLCFG60 — Pullup/Pulldown configuration for GPIO 60
    values as PINCFG40.PULLCFG40
  [12] SR60 — Configure the slew rate
  [11:10] DS60 — Drive strength selection for GPIO 60
    values as PINCFG50.DS50
  [9:8] OUTCFG60 — Pin IO mode selection for GPIO pin 60
    values as PINCFG40.OUTCFG40
  [7:6] IRPTEN60 — Interrupt enable for GPIO 60
    values as PINCFG40.IRPTEN40
  [5] RDZERO60 — Return 0 for read data on GPIO 60
  [4] INPEN60 — Input enable for GPIO 60
  [3:0] FNCSEL60 — Function select for GPIO pin 60
    1=TRIG1 (ADC trigger input); 3=GPIO (General purpose I/O); 4=UART0TX (UART transmit output (UART 0)); 5=UART3CTS (UART Clear to Send (CTS) (UART 3)); 6=CT60 (Timer/Counter input or output; Selection of direction is done via CTIMER register settings.); 7=NCE60 (IOMSTR/MSPI N Chip Select. Polarity is determined by CE_POLARITY field); 8=OBSBUS12 (Observation bus bit 12); 11=FPIO (Fast PIO)
0xF4 PINCFG61 reset 0x3 — Controls the operation of GPIO pin 61.
  [27] FOEN61 — Force output enable active regardless of function selected. Otherwise the selected function will enable the output only when needed
  [26] FIEN61 — Force input enable active regardless of function selected. Otherwise the selected function will enable the input only when needed
  [22] NCEPOL61 — Polarity select for NCE for GPIO 61
    values as PINCFG40.NCEPOL40
  [21:16] NCESRC61 — IOMSTR/MSPI N Chip Select 61, DISP control signals DE, CSX, and CS. Polarity is determined by CE_POLARITY field
    values as PINCFG40.NCESRC40
  [15:13] PULLCFG61 — Pullup/Pulldown configuration for GPIO 61
    values as PINCFG40.PULLCFG40
  [12] SR61 — Configure the slew rate
  [11:10] DS61 — Drive strength selection for GPIO 61
    values as PINCFG40.DS40
  [9:8] OUTCFG61 — Pin IO mode selection for GPIO pin 61
    values as PINCFG40.OUTCFG40
  [7:6] IRPTEN61 — Interrupt enable for GPIO 61
    values as PINCFG40.IRPTEN40
  [5] RDZERO61 — Return 0 for read data on GPIO 61
  [4] INPEN61 — Input enable for GPIO 61
  [3:0] FNCSEL61 — Function select for GPIO pin 61
    0=M6SCL (Serial I2C Master Clock output (IOM 6)); 1=M6SCK (Serial SPI Master Clock output (IOM 6)); 2=I2S1_CLK (Bidirectional I2S Bit clock. Operates in output mode in master mode and input mode for slave mode. (I2S Master/Slave 2)); 3=GPIO (General purpose I/O); 4=UART2TX (UART transmit output (UART 2)); 5=UART3TX (UART transmit output (UART 3)); 6=CT61 (Timer/Counter input or output; Selection of direction is done via CTIMER register settings.); 7=NCE61 (IOMSTR/MSPI N Chip Select. Polarity is determined by CE_POLARITY field); 8=OBSBUS13 (Observation bus bit 13); 10=I3CM0_SCL (Serial I3C Master Clock output (IOM 0)); 11=FPIO (Fast PIO)
